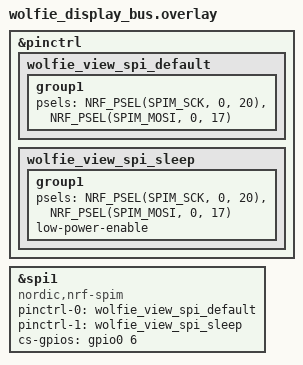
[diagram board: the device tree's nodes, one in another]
/* Dedicated nice!view SPI1: PMW3610 SPI0 remains untouched. */
#include <zephyr/dt-bindings/gpio/gpio.h>
#include <zephyr/dt-bindings/pinctrl/nrf-pinctrl.h>

&pinctrl {
    wolfie_view_spi_default: wolfie_view_spi_default {
        group1 {
            psels = <NRF_PSEL(SPIM_SCK, 0, 20)>,
                    <NRF_PSEL(SPIM_MOSI, 0, 17)>;
        };
    };
    wolfie_view_spi_sleep: wolfie_view_spi_sleep {
        group1 {
            psels = <NRF_PSEL(SPIM_SCK, 0, 20)>,
                    <NRF_PSEL(SPIM_MOSI, 0, 17)>;
            low-power-enable;
        };
    };
};

nice_view_spi: &spi1 {
    status = "okay";
    compatible = "nordic,nrf-spim";
    pinctrl-0 = <&wolfie_view_spi_default>;
    pinctrl-1 = <&wolfie_view_spi_sleep>;
    pinctrl-names = "default", "sleep";
    cs-gpios = <&gpio0 6 GPIO_ACTIVE_HIGH>;
};
